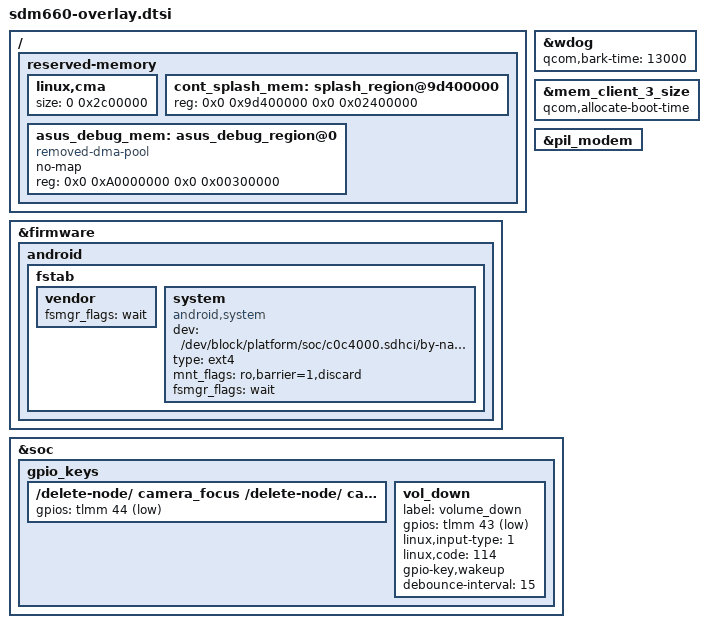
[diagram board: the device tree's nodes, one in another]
/* SPDX-License-Identifier: GPL-2.0 */

/ {
	reserved-memory {
		linux,cma {
			size = <0 0x2c00000>;
		};

		cont_splash_mem: splash_region@9d400000 {
			reg = <0x0 0x9d400000 0x0 0x02400000>;
		};

		/delete-node/ dfps_data_mem@0x9f7ff000;

		asus_debug_mem: asus_debug_region@0 {
			compatible = "removed-dma-pool";
            no-map;
			reg = <0x0 0xA0000000 0x0 0x00300000>;
		};
	};
};

&firmware {
	android {
		fstab {
			vendor {
				fsmgr_flags = "wait";
				status = "ok";
			};

			system {
				compatible = "android,system";
				dev = "/dev/block/platform/soc/c0c4000.sdhci/by-name/system";
				type = "ext4";
				mnt_flags = "ro,barrier=1,discard";
				fsmgr_flags = "wait";
				status = "ok";
			};
		};
	};
};

&wdog {
	qcom,bark-time = <13000>;
};

&mem_client_3_size {
		/delete-property/ qcom,allocate-on-request;

		qcom,allocate-boot-time;
};

&pil_modem {
	/delete-property/ qcom,complete-ramdump;
};

&soc {
	gpio_keys {
		/delete-node/ camera_focus
		/delete-node/ camera_snapshot
		
		vol_up {
			gpios = <&tlmm 44 0x1>;
		};
		
		vol_down {
			label = "volume_down";
			gpios = <&tlmm 43 0x1>;
			linux,input-type = <1>;
			linux,code = <114>;
			gpio-key,wakeup;
			debounce-interval = <15>;
		};
	};
};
